# S32K324_M7 register map
Vendor: NXP Semiconductors; File version: 1.1
CPU: CM7 r0p1, little endian, MPU, FPU, VTOR, 4 interrupt priority bits
Registers are 32-bit, read-write, reset 0x0 unless marked. A register's access mark holds for its fields unless they carry their own. Offsets are from the block's base; [hi:lo] are bit positions; {n}, {i} and the like mark numbered series.

## MU_2__MUA — MUA
Base 0x400B8000
Same registers: MU_2__MUB 0x400BC000
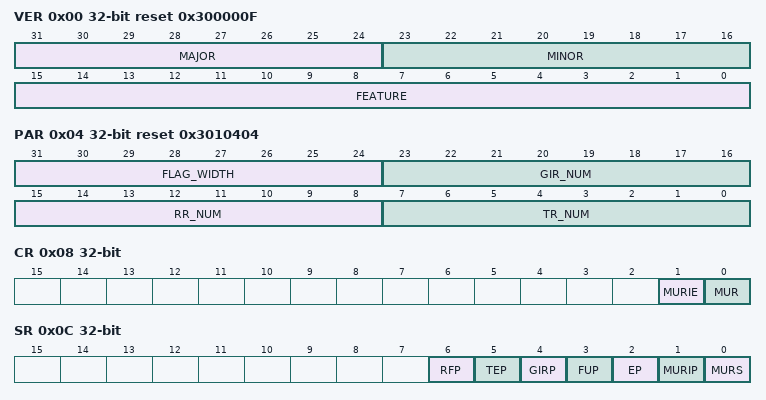
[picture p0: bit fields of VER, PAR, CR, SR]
0x00 VER ro reset 0x300000F — Version ID Register
  [31:24] MAJOR — Major Version Number
  [23:16] MINOR — Minor Version Number
  [15:0] FEATURE — Feature Set Number
0x04 PAR ro reset 0x3010404 — Parameter Register
  [31:24] FLAG_WIDTH
  [23:16] GIR_NUM — General Interrupt Request Number
  [15:8] RR_NUM — RR Number
  [7:0] TR_NUM — Transmit Register Number
0x08 CR — Control Register
  [1] MURIE — MUA Reset Interrupt Enable
    0=zero (Disables Processor A-side MU Reset Interrupt request due to MU reset issued by MUB.); 1=one (Enables Processor A-side MU Reset Interrupt request due to MU reset issued by MUB.)
  [0] MUR — MU Reset
    0=zero (Self clearing bit.); 1=one (Asserts the MU reset.)
0x0C SR (reset mask 0xFFFFFFFE) — Status Register
  [6] RFP ro — MUA Receive Full Pending Flag
    0=zero (No TRn register is written by MUB.); 1=one (Any TRn register is written by MUB.)
  [5] TEP ro — MUA Transmit Empty Pending
    0=zero (RRn register is not read by MUB.); 1=one (Any RRn register is read by MUB.)
  [4] GIRP ro — MUA General Interrupt Pending
    0=zero (No general interrupt request is sent from MUB.); 1=one (Any general interrupt request is sent from MUB.)
  [3] FUP ro — MUA Flags Update Pending
    0=zero (No pending update flags(initiated by MUA) are in process); 1=one (Pending update flags(initiated by MUA) are in process)
  [2] EP ro — MUA Side Event Pending
    0=zero (The MUA side event is not pending.); 1=one (The MUA side event is pending.)
  [1] MURIP write-1-clears — MU Reset Interrupt Pending
    0=zero (Processor B did not issue MU reset.); 1=one (Processor B issued MU reset.)
  [0] MURS ro — MUA and MUB Reset State
    0=zero (MUA and MUB are out of reset.); 1=one (MUA or MUB is in reset state.)
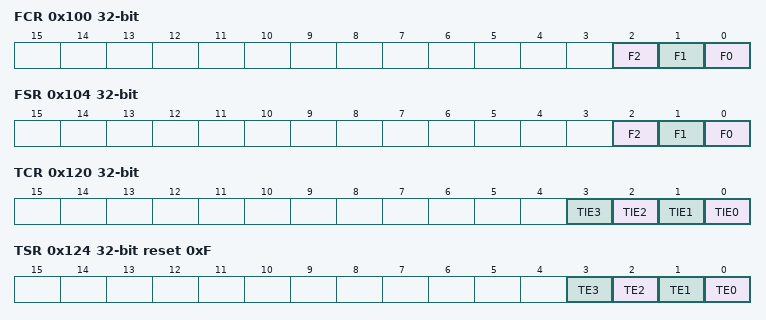
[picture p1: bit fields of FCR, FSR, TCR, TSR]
0x100 FCR — Flag Control Register
  [all] fields
    0=zero (Clears the Fn bit in the FSR register.); 1=one (Sets the Fn bit in the FSR register.)
  [2] F2 — MUA to MUB Flag n
  [1] F1 — MUA to MUB Flag n
  [0] F0 — MUA to MUB Flag n
0x104 FSR ro — Flag Status Register
  [all] fields
    0=zero (Fn bit in the MUB FCR register is written 0.); 1=one (Fn bit in the MUB FCR register is written 1.)
  [2] F2 — MUB to MUA Side Flag n
  [1] F1 — MUB to MUA Side Flag n
  [0] F0 — MUB to MUA Side Flag n
0x110 GIER — General Interrupt Enable Register
  [0] GIE0 — MUA General Purpose Interrupt Enable n
    0=zero (Disables MUA General Interrupt n.); 1=one (Enables MUA General Interrupt n.)
0x114 GCR — General Control Register
  [0] GIR0 — MUA General Purpose Interrupt Request n
    0=zero (MUA General Interrupt n is not requested to the MUB.); 1=one (MUA General Interrupt n is requested to the MUB.)
0x118 GSR write-1-clears — General Status Register
  [0] GIP0 write-1-clears — MUA General Interrupt Request Pending n
    0=zero (MUA general purpose interrupt n is not pending.); 1=one (MUA general purpose interrupt n is pending.)
0x120 TCR — Transmit Control Register
  [all] fields
    0=zero (Disables MUA Transmit Interrupt n. (default)); 1=one (Enables MUA Transmit Interrupt n.)
  [n] TIE{n} (n=0..3) — MUA Transmit Interrupt Enable n
0x124 TSR ro reset 0xF — Transmit Status Register
  [all] fields
    0=zero (MUA TRn register is not empty.); 1=one (MUA TRn register is empty.)
  [n] TE{n} (n=0..3) — MUA Transmit Register n Empty
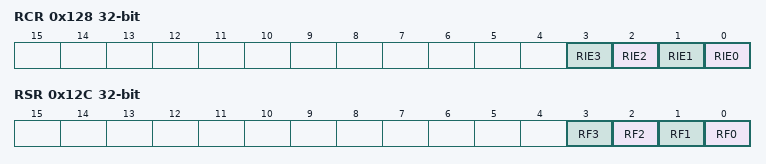
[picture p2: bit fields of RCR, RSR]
0x128 RCR — Receive Control Register
  [all] fields
    0=zero (Disables MUA Receive Interrupt n.); 1=one (Enables MUA Receive Interrupt n.)
  [n] RIE{n} (n=0..3) — MUA Receive Interrupt Enable n
0x12C RSR ro — Receive Status Register
  [all] fields
    0=zero (MUA RRn register is not full.); 1=one (MUA RRn register has received data from MUB TRn register and is ready to be read by the MUA.)
  [n] RF{n} (n=0..3) — MUA Receive Register n Full
{0x200+4i} TR[{i}] (i=0..3) — Transmit Register
  [31:0] TR_DATA — MUA Transmit Data
{0x280+4i} RR[{i}] (i=0..3) ro — Receive Register
  [31:0] RR_DATA — MUA Receive Data
